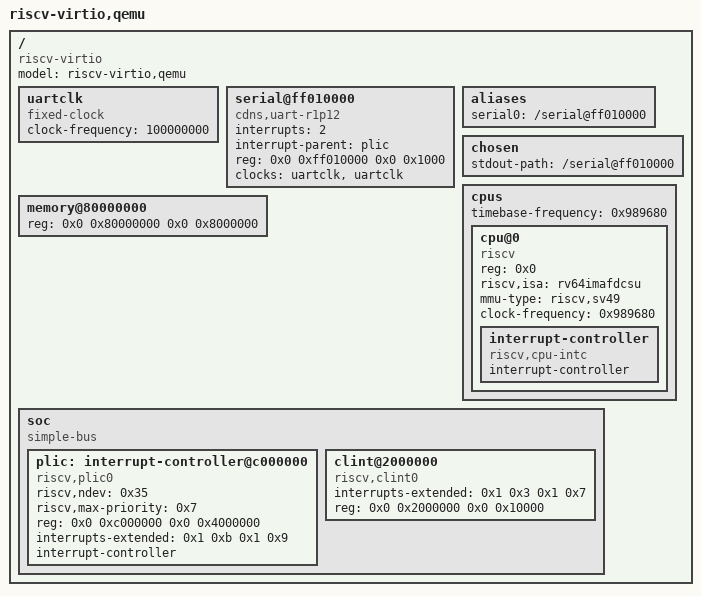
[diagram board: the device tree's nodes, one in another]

/dts-v1/;

/ {
	#address-cells = <0x2>;
	#size-cells = <0x2>;
	compatible = "riscv-virtio";
	model = "riscv-virtio,qemu";



	uartclk: uartclk {
        compatible = "fixed-clock";
        #clock-cells = <0>;
        clock-frequency = <100000000>;
    };

	serial@ff010000 {
        compatible = "cdns,uart-r1p12";
        status = "okay";
        interrupts = <2>;
        interrupt-parent = <&plic>;
        reg = <0x0 0xff010000 0x0 0x1000>;
        clock-names = "uart_clk", "pclk";
        clocks = <&uartclk>, <&uartclk>;
    };

	aliases {
        serial0 = "/serial@ff010000";
    };

	chosen {
        stdout-path = "/serial@ff010000";
    };

	cpus {
		#address-cells = <0x1>;
		#size-cells = <0x0>;
		timebase-frequency = <0x989680>;

		cpu@0 {
			device_type = "cpu";
			reg = <0x0>;
			status = "okay";
			compatible = "riscv";
			riscv,isa = "rv64imafdcsu";
			mmu-type = "riscv,sv49";
			clock-frequency = <0x989680>;

			interrupt-controller {
				#interrupt-cells = <0x1>;
				interrupt-controller;
				compatible = "riscv,cpu-intc";
				linux,phandle = <0x1>;
				phandle = <0x1>;
			};
		};
	};

	memory@80000000 {
		device_type = "memory";
		reg = <0x0 0x80000000 0x0 0x8000000>;

	};

	soc {
		#address-cells = <0x2>;
		#size-cells = <0x2>;
		compatible = "simple-bus";
		ranges;

		plic: interrupt-controller@c000000 {
			linux,phandle = <0x2>;
			phandle = <0x2>;
			riscv,ndev = <0x35>;
			riscv,max-priority = <0x7>;
			reg-names = "control";
			reg = <0x0 0xc000000 0x0 0x4000000>;
			interrupts-extended = <0x1 0xb 0x1 0x9>;
			interrupt-controller;
			compatible = "riscv,plic0";
			#interrupt-cells = <0x1>;
			#address-cells = <0x0>;
		};

		clint@2000000 {
			interrupts-extended = <0x1 0x3 0x1 0x7>;
			reg = <0x0 0x2000000 0x0 0x10000>;
			compatible = "riscv,clint0";
		};
	};
};
